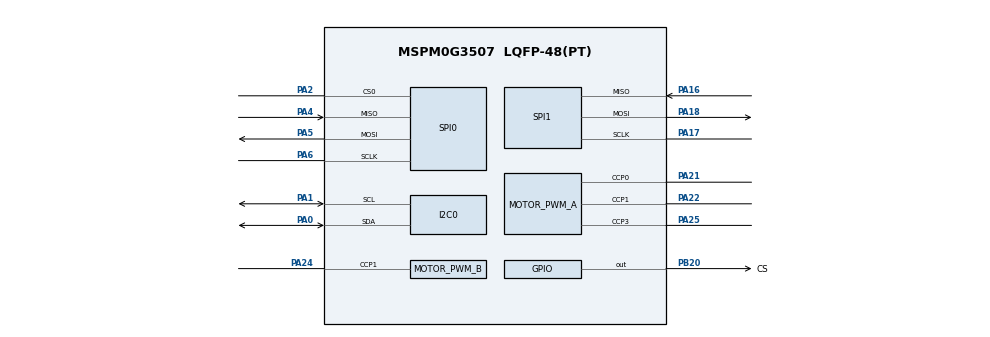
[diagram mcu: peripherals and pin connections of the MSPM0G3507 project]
/**
 * MSPM0G3507 LQFP-48 comprehensive pin plan.
 *
 * Corrections required by the official MSPM0G3507 IOMUX definitions:
 *   M3_IN2: PB11 -> PB9
 *   M4_IN1: PB12 -> PB19
 *   M4_IN2: PB13 -> PB24
 *   SPI1_SCLK: PA15 -> PA17
 *   SPI1_PICO: PA17 -> PA18
 *   M3_IN1: PA18 -> PA15
 *   ENC4_A: PB17 -> PA31 (PB17 is wired to the on-board Flash CS)
 */
//@cliArgs --device "MSPM0G350X" --package "LQFP-48(PT)" --part "Default"
//@v2CliArgs --device "MSPM0G3507" --package "LQFP-48(PT)"

const GPIO = scripting.addModule("/ti/driverlib/GPIO", {}, false);
const MOTOR_DIR = GPIO.addInstance();
const ENCODER = GPIO.addInstance();
const ICM42688 = GPIO.addInstance();
const I2C = scripting.addModule("/ti/driverlib/I2C", {}, false);
const I2C0 = I2C.addInstance();
const PWM = scripting.addModule("/ti/driverlib/PWM", {}, false);
const MOTOR_PWM_A = PWM.addInstance();
const MOTOR_PWM_B = PWM.addInstance();
const SPI = scripting.addModule("/ti/driverlib/SPI", {}, false);
const SPI0 = SPI.addInstance();
const SPI1 = SPI.addInstance();
const UART = scripting.addModule("/ti/driverlib/UART", {}, false);
const UART0 = UART.addInstance();
const UART1 = UART.addInstance();
const UART2 = UART.addInstance();
const UART3 = UART.addInstance();
const SYSCTL = scripting.addModule("/ti/driverlib/SYSCTL");
const Board = scripting.addModule("/ti/driverlib/Board", {}, false);

/* SPI0: PA2/PA4/PA5/PA6, full-duplex DMA on CH0/CH1. */
SPI0.$name = "SPI0";
SPI0.mode = "CONTROLLER";
SPI0.targetBitRate = 1000000;
SPI0.dataSize = 8;
SPI0.peripheral.$assign = "SPI0";
SPI0.peripheral.cs0Pin.$assign = "PA2";
SPI0.peripheral.misoPin.$assign = "PA4";
SPI0.peripheral.mosiPin.$assign = "PA5";
SPI0.peripheral.sclkPin.$assign = "PA6";
SPI0.enabledDMAEvent1Triggers = "DL_SPI_DMA_INTERRUPT_RX";
SPI0.enableDMAEvent1 = true;
SPI0.enabledDMAEvent2Triggers = "DL_SPI_DMA_INTERRUPT_TX";
SPI0.enableDMAEvent2 = true;
SPI0.DMA_CHANNEL_EVENT1.$name = "DMA_SPI0_RX";
SPI0.DMA_CHANNEL_EVENT1.addressMode = "f2b";
SPI0.DMA_CHANNEL_EVENT1.srcLength = "BYTE";
SPI0.DMA_CHANNEL_EVENT1.dstLength = "BYTE";
SPI0.DMA_CHANNEL_EVENT1.peripheral.$assign = "DMA_CH0";
SPI0.DMA_CHANNEL_EVENT2.$name = "DMA_SPI0_TX";
SPI0.DMA_CHANNEL_EVENT2.addressMode = "b2f";
SPI0.DMA_CHANNEL_EVENT2.srcLength = "BYTE";
SPI0.DMA_CHANNEL_EVENT2.dstLength = "BYTE";
SPI0.DMA_CHANNEL_EVENT2.peripheral.$assign = "DMA_CH1";

/* SPI1: PA16/PA17/PA18, software-controlled ICM42688 CS on PB20. */
SPI1.$name = "SPI1";
SPI1.mode = "CONTROLLER";
SPI1.targetBitRate = 1000000;
SPI1.dataSize = 8;
SPI1.frameFormat = "MOTO3";
SPI1.chipSelect = [];
SPI1.peripheral.$assign = "SPI1";
SPI1.peripheral.misoPin.$assign = "PA16";
SPI1.peripheral.mosiPin.$assign = "PA18";
SPI1.peripheral.sclkPin.$assign = "PA17";
SPI1.enabledDMAEvent1Triggers = "DL_SPI_DMA_INTERRUPT_RX";
SPI1.enableDMAEvent1 = true;
SPI1.enabledDMAEvent2Triggers = "DL_SPI_DMA_INTERRUPT_TX";
SPI1.enableDMAEvent2 = true;
SPI1.DMA_CHANNEL_EVENT1.$name = "DMA_SPI1_RX";
SPI1.DMA_CHANNEL_EVENT1.addressMode = "f2b";
SPI1.DMA_CHANNEL_EVENT1.srcLength = "BYTE";
SPI1.DMA_CHANNEL_EVENT1.dstLength = "BYTE";
SPI1.DMA_CHANNEL_EVENT1.peripheral.$assign = "DMA_CH2";
SPI1.DMA_CHANNEL_EVENT2.$name = "DMA_SPI1_TX";
SPI1.DMA_CHANNEL_EVENT2.addressMode = "b2f";
SPI1.DMA_CHANNEL_EVENT2.srcLength = "BYTE";
SPI1.DMA_CHANNEL_EVENT2.dstLength = "BYTE";
SPI1.DMA_CHANNEL_EVENT2.peripheral.$assign = "DMA_CH3";

/* ICM42688 software chip select. Keep high whenever no SPI transaction is active. */
ICM42688.$name = "ICM42688";
ICM42688.associatedPins.create(1);
ICM42688.associatedPins[0].$name = "CS";
ICM42688.associatedPins[0].direction = "OUTPUT";
ICM42688.associatedPins[0].initialValue = "SET";
ICM42688.associatedPins[0].assignedPort = "PORTB";
ICM42688.associatedPins[0].assignedPin = "20";
ICM42688.associatedPins[0].pin.$assign = "PB20";

/* I2C0 controller on PA0/PA1. */
I2C0.$name = "I2C0";
I2C0.basicEnableController = true;
I2C0.peripheral.$assign = "I2C0";
I2C0.peripheral.sdaPin.$assign = "PA0";
I2C0.peripheral.sclPin.$assign = "PA1";
I2C0.sdaPinConfig.enableConfig = true;
I2C0.sclPinConfig.enableConfig = true;

/* Four UART routes from the supplied pin plan. */
const uartConfig = [
    [UART0, "UART0", "PA10", "PA11"],
    [UART1, "UART1", "PA8", "PA9"],
    [UART2, "UART2", "PB15", "PB16"],
    [UART3, "UART3", "PB2", "PB3"],
];
for (let i = 0; i < uartConfig.length; i++) {
    const instance = uartConfig[i][0];
    instance.$name = uartConfig[i][1];
    instance.targetBaudRate = 115200;
    instance.enableFIFO = true;
    instance.peripheral.$assign = uartConfig[i][1];
    instance.peripheral.txPin.$assign = uartConfig[i][2];
    instance.peripheral.rxPin.$assign = uartConfig[i][3];
}

/* TIMA0 provides M1/M2/M4 PWM on CC0/CC1/CC3. */
MOTOR_PWM_A.$name = "MOTOR_PWM_A";
MOTOR_PWM_A.ccIndex = [0, 1, 3];
MOTOR_PWM_A.timerCount = 1000;
MOTOR_PWM_A.timerStartTimer = true;
MOTOR_PWM_A.enableShadowLoad = true;
MOTOR_PWM_A.dutyArgs = "[0,0,0,0]";
MOTOR_PWM_A.clockDivider = 1;
MOTOR_PWM_A.clockPrescale = 1;
MOTOR_PWM_A.peripheral.$assign = "TIMA0";
MOTOR_PWM_A.peripheral.ccp0Pin.$assign = "PA21";
MOTOR_PWM_A.peripheral.ccp1Pin.$assign = "PA22";
MOTOR_PWM_A.peripheral.ccp3Pin.$assign = "PA25";
MOTOR_PWM_A.PWM_CHANNEL_0.$name = "M1_PWM_CC0";
MOTOR_PWM_A.PWM_CHANNEL_1.$name = "M2_PWM_CC1";
MOTOR_PWM_A.PWM_CHANNEL_3.$name = "M4_PWM_CC3";

/* TIMA1 provides M3 PWM on CC1. */
MOTOR_PWM_B.$name = "MOTOR_PWM_B";
MOTOR_PWM_B.ccIndex = [1];
MOTOR_PWM_B.timerCount = 1000;
MOTOR_PWM_B.timerStartTimer = true;
MOTOR_PWM_B.enableShadowLoad = true;
MOTOR_PWM_B.dutyArgs = "[0,0,0,0]";
MOTOR_PWM_B.clockDivider = 1;
MOTOR_PWM_B.clockPrescale = 1;
MOTOR_PWM_B.peripheral.$assign = "TIMA1";
MOTOR_PWM_B.peripheral.ccp1Pin.$assign = "PA24";
MOTOR_PWM_B.PWM_CHANNEL_1.$name = "M3_PWM_CC1";

/* Eight TB6612 direction outputs plus shared standby. */
MOTOR_DIR.$name = "MOTOR_DIR";
MOTOR_DIR.associatedPins.create(9);
const motorDirPins = [
    ["M1_IN1", "PORTB", "6", "PB6"],
    ["M1_IN2", "PORTB", "7", "PB7"],
    ["M2_IN1", "PORTB", "8", "PB8"],
    ["M2_IN2", "PORTA", "7", "PA7"],
    ["M3_IN1", "PORTA", "15", "PA15"],
    ["M3_IN2", "PORTB", "9", "PB9"],
    ["M4_IN1", "PORTB", "19", "PB19"],
    ["M4_IN2", "PORTB", "24", "PB24"],
    ["STBY", "PORTA", "23", "PA23"],
];
for (let i = 0; i < motorDirPins.length; i++) {
    MOTOR_DIR.associatedPins[i].$name = motorDirPins[i][0];
    MOTOR_DIR.associatedPins[i].direction = "OUTPUT";
    MOTOR_DIR.associatedPins[i].initialValue = "CLEARED";
    MOTOR_DIR.associatedPins[i].assignedPort = motorDirPins[i][1];
    MOTOR_DIR.associatedPins[i].assignedPin = motorDirPins[i][2];
    MOTOR_DIR.associatedPins[i].pin.$assign = motorDirPins[i][3];
}

/* Four quadrature encoders, decoded by GPIO both-edge interrupts. */
ENCODER.$name = "ENCODER";
ENCODER.associatedPins.create(8);
const encoderPins = [
    ["ENC1_A", "PORTA", "12", "PA12"],
    ["ENC1_B", "PORTA", "13", "PA13"],
    ["ENC2_A", "PORTA", "14", "PA14"],
    ["ENC2_B", "PORTA", "26", "PA26"],
    ["ENC3_A", "PORTA", "27", "PA27"],
    ["ENC3_B", "PORTA", "28", "PA28"],
    ["ENC4_A", "PORTA", "31", "PA31"],
    ["ENC4_B", "PORTB", "18", "PB18"],
];
for (let i = 0; i < encoderPins.length; i++) {
    ENCODER.associatedPins[i].$name = encoderPins[i][0];
    ENCODER.associatedPins[i].direction = "INPUT";
    ENCODER.associatedPins[i].interruptEn = true;
    ENCODER.associatedPins[i].polarity = "RISE_FALL";
    ENCODER.associatedPins[i].assignedPort = encoderPins[i][1];
    ENCODER.associatedPins[i].assignedPin = encoderPins[i][2];
    ENCODER.associatedPins[i].pin.$assign = encoderPins[i][3];
}

SYSCTL.forceDefaultClkConfig = true;
SYSCTL.clockTreeEn = true;

/* Keep the debugger and reset functions reserved. */
Board.peripheral.$suggestSolution = "DEBUGSS";
Board.peripheral.swclkPin.$suggestSolution = "PA20";
Board.peripheral.swdioPin.$suggestSolution = "PA19";
